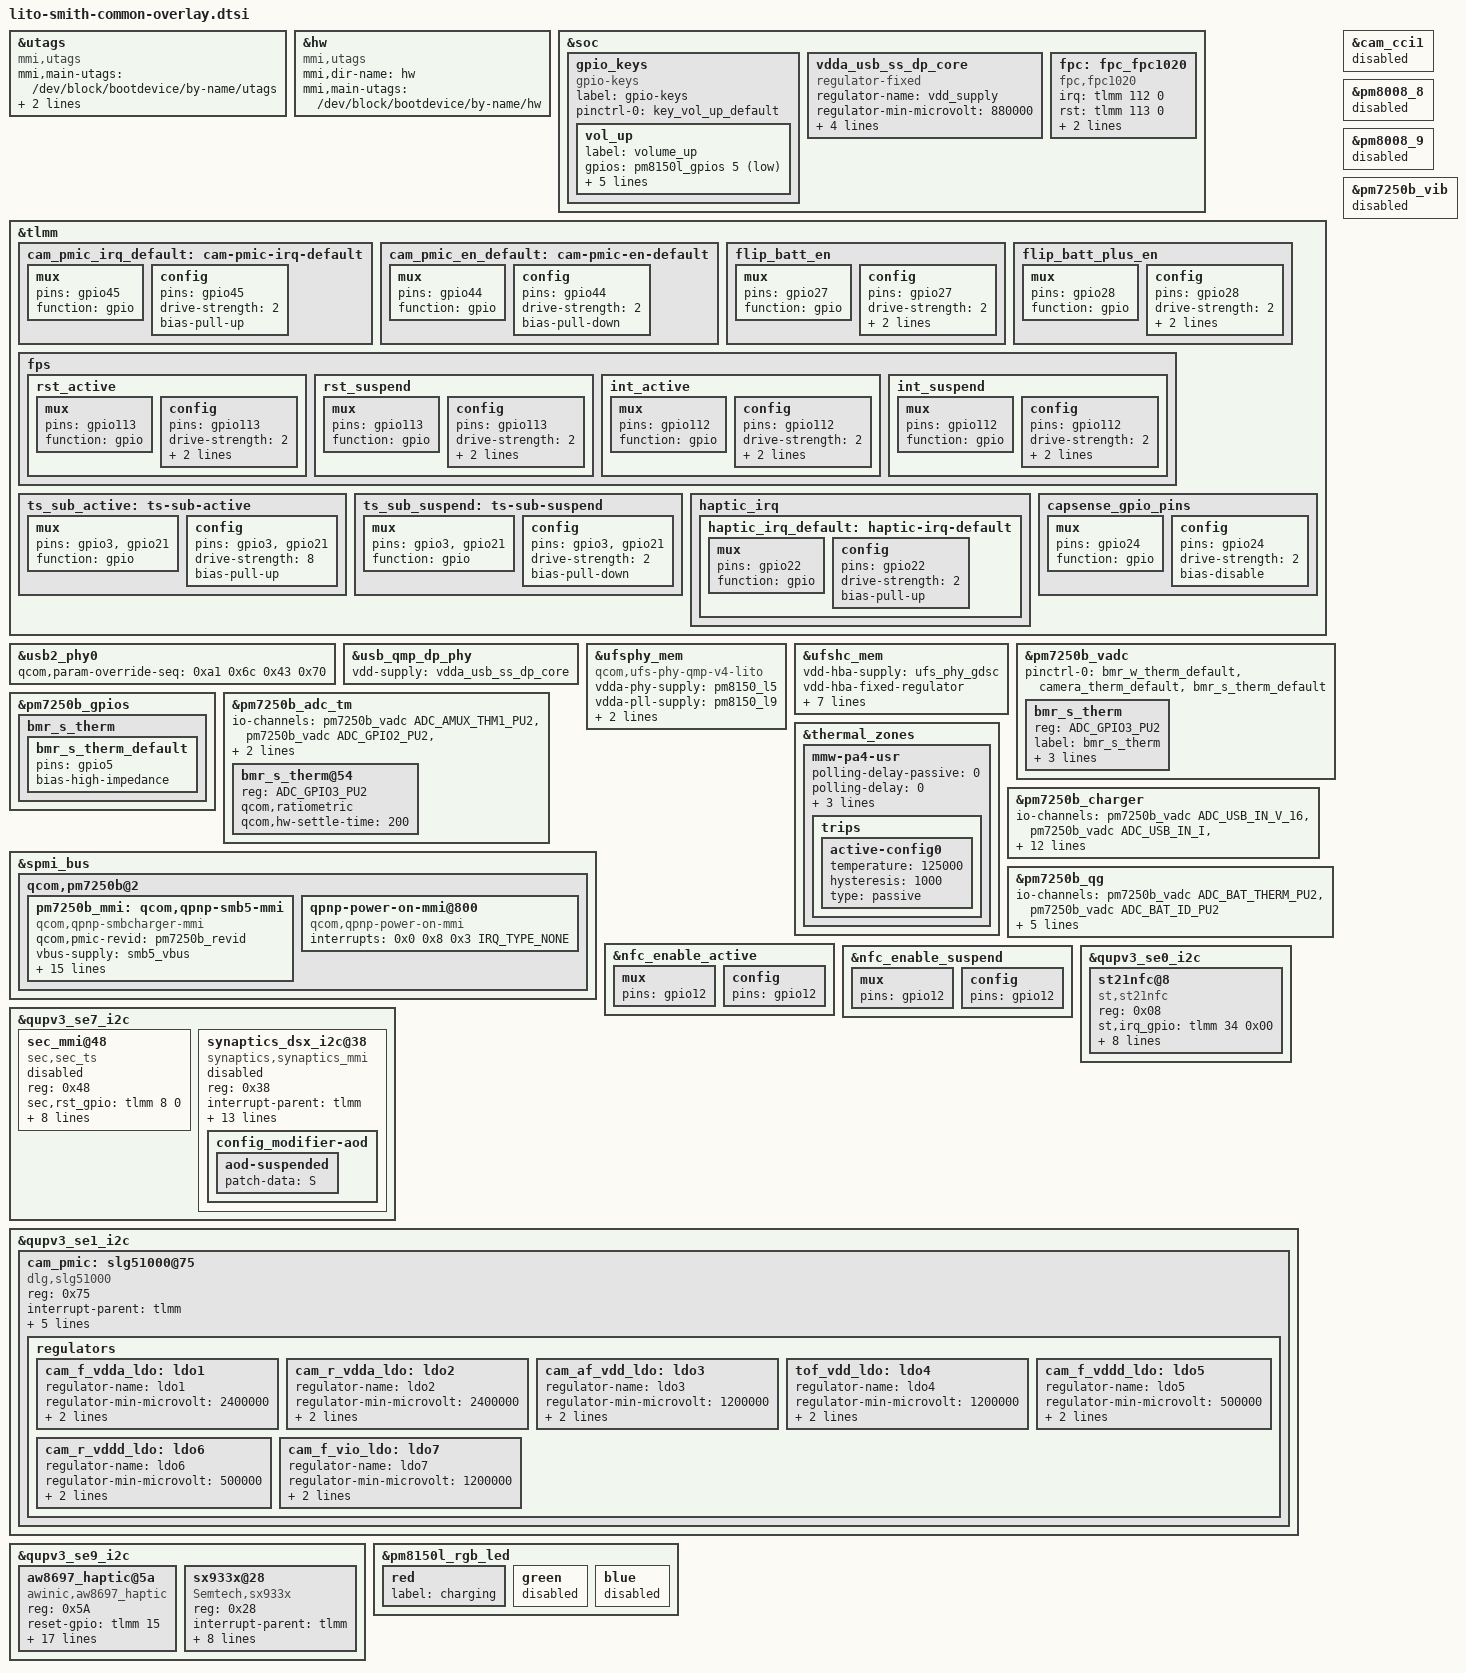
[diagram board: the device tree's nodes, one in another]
#include <dt-bindings/interrupt-controller/arm-gic.h>
#include <dt-bindings/gpio/gpio.h>
#include "carrier-channel-ids.dtsi"
#include "lito-pmic-overlay.dtsi"
#include "lito-thermal-overlay.dtsi"
#include "camera/lito-camera-sensor-mot-smith.dtsi"

&utags {
	compatible = "mmi,utags";
	mmi,main-utags = "/dev/block/bootdevice/by-name/utags";
	mmi,backup-utags = "/dev/block/bootdevice/by-name/utagsBackup";
};

&hw {
	compatible = "mmi,utags";
	mmi,dir-name = "hw";
	mmi,main-utags = "/dev/block/bootdevice/by-name/hw";
};

&soc {
	gpio_keys {
		compatible = "gpio-keys";
		label = "gpio-keys";

		pinctrl-names = "default";
		pinctrl-0 = <&key_vol_up_default>;

		vol_up {
			label = "volume_up";
			gpios = <&pm8150l_gpios 5 GPIO_ACTIVE_LOW>;
			linux,input-type = <1>;
			linux,code = <KEY_VOLUMEUP>;
			gpio-key,wakeup;
			debounce-interval = <15>;
			linux,can-disable;
		};
	};

	vdda_usb_ss_dp_core: vdda_usb_ss_dp_core {
		compatible = "regulator-fixed";
		regulator-name = "vdd_supply";
		regulator-min-microvolt = <880000>;
		regulator-max-microvolt = <880000>;
		enable-active-high;
		gpio = <&pm8150l_gpios 12 GPIO_ACTIVE_HIGH>;
		pinctrl-names = "default";
		pinctrl-0 = <&usb_eldo13>;
	};

	fpc: fpc_fpc1020 {
		compatible = "fpc,fpc1020";
		status = "ok";
		irq = <&tlmm 112 0>;
		rst = <&tlmm 113 0>;
		pinctrl-names = "default", "suspend";
		pinctrl-0 = <&int_active &rst_active>;
		pinctrl-1 = <&int_suspend &rst_suspend>;
	};
};

&tlmm{
	cam_pmic_irq_default: cam-pmic-irq-default {
		mux {
			pins = "gpio45";
			function = "gpio";
		};
		config {
		        pins = "gpio45";
			drive-strength = <2>; /* 2 mA */
			bias-pull-up;
		};
	};

	cam_pmic_en_default: cam-pmic-en-default {
		mux {
			pins = "gpio44";
			function = "gpio";
		};
		config {
			pins = "gpio44";
			drive-strength = <2>;
			bias-pull-down;
		};
	};

	flip_batt_en: flip_batt_en {
		mux {
			pins = "gpio27";
			function = "gpio";
		};
		config {
			pins = "gpio27";
			drive-strength = <2>;
			bias-pull-up;
			output-high;
		};
	};

	flip_batt_plus_en: flip_batt_plus_en {
		mux {
			pins = "gpio28";
			function = "gpio";
		};
		config {
			pins = "gpio28";
			drive-strength = <2>;
			bias-pull-up;
			output-high;
		};
	};

	fps {
		rst_active: rst_active {
			mux {
				pins = "gpio113";
				function = "gpio";
			};
			config {
				pins = "gpio113";
				drive-strength = <2>;
				bias-disable;
				output-low;
			};
		};

		rst_suspend: rst_suspend{
			mux {
				pins = "gpio113";
				function = "gpio";
			};

			config {
				pins = "gpio113";
				drive-strength = <2>;
				bias-pull-down;
				output-high;
			};
		};

		int_active: int_active {
			mux {
				pins = "gpio112";
				function = "gpio";
			};

			config {
				pins = "gpio112";
				drive-strength = <2>;
				bias-pull-down;
				input-enable;
			};
		};

		int_suspend: int_suspend{
			mux {
				pins = "gpio112";
				function = "gpio";
			};

			config {
				pins = "gpio112";
				drive-strength = <2>;
				bias-pull-down;
				input-enable;
			};
		};
	};

	ts_sub_active: ts-sub-active {
		mux {
			pins = "gpio3", "gpio21";
			function = "gpio";
		};
		config {
			pins = "gpio3", "gpio21";
			drive-strength = <8>;
			bias-pull-up;
		};
	};

	ts_sub_suspend: ts-sub-suspend {
		mux {
			pins = "gpio3", "gpio21";
			function = "gpio";
		};
		config {
			pins = "gpio3", "gpio21";
			drive-strength = <2>;
			bias-pull-down;
		};
	};
};

&usb2_phy0 {
	qcom,param-override-seq = <0xa1 0x6c
				0x43 0x70>;
};

&usb_qmp_dp_phy {
	vdd-supply = <&vdda_usb_ss_dp_core>;
};

&ufsphy_mem {
	compatible = "qcom,ufs-phy-qmp-v4-lito";

	vdda-phy-supply = <&pm8150_l5>;
	vdda-pll-supply = <&pm8150_l9>;
	vdda-phy-max-microamp = <90200>;
	vdda-pll-max-microamp = <19000>;

	status = "ok";
};

&ufshc_mem {
	vdd-hba-supply = <&ufs_phy_gdsc>;
	vdd-hba-fixed-regulator;
	vcc-supply = <&pm8150a_l7>;
	vcc-voltage-level = <2950000 2960000>;
	vccq2-supply = <&pm8150_s4>;
	vcc-max-microamp = <800000>;
	vccq2-max-microamp = <800000>;

	qcom,vddp-ref-clk-supply = <&pm8150_l9>;
	qcom,vddp-ref-clk-max-microamp = <100>;

	status = "ok";
};

&pm7250b_vadc {
	pinctrl-0 = <
		&bmr_w_therm_default
		&camera_therm_default
		&bmr_s_therm_default
	>;

	bmr_s_therm {
		reg = <ADC_GPIO3_PU2>;
		label = "bmr_s_therm";
		qcom,ratiometric;
		qcom,hw-settle-time = <200>;
		qcom,pre-scaling = <1 1>;
	};
};

&pm7250b_gpios {
	bmr_s_therm {
		bmr_s_therm_default: bmr_s_therm_default {
			pins = "gpio5";
			bias-high-impedance;
		};
	};
};

&pm7250b_adc_tm {
	io-channels = <&pm7250b_vadc ADC_AMUX_THM1_PU2>,
			<&pm7250b_vadc ADC_GPIO2_PU2>,
			<&pm7250b_vadc ADC_GPIO3_PU2>,
			<&pm7250b_vadc ADC_GPIO4_PU2>;

	bmr_s_therm@54 {
		reg = <ADC_GPIO3_PU2>;
		qcom,ratiometric;
		qcom,hw-settle-time = <200>;
	};
};

&thermal_zones {
	mmw-pa4-usr {
		polling-delay-passive = <0>;
		polling-delay = <0>;
		thermal-governor = "user_space";
		thermal-sensors = <&pm7250b_adc_tm ADC_GPIO3_PU2>;
		wake-capable-sensor;
		trips {
			active-config0 {
				temperature = <125000>;
				hysteresis = <1000>;
				type = "passive";
			};
		};
	};
};

&pm7250b_charger {
	status = "ok";
	io-channels = <&pm7250b_vadc ADC_USB_IN_V_16>,
		      <&pm7250b_vadc ADC_USB_IN_I>,
		      <&pm7250b_vadc ADC_CHG_TEMP>,
		      <&pm7250b_vadc ADC_DIE_TEMP>,
		      <&pm7250b_vadc ADC_AMUX_THM3_PU2>,
		      <&pm7250b_vadc ADC_SBUx>,
		      <&pm7250b_vadc ADC_VPH_PWR>;
	io-channel-names = "usb_in_voltage",
			   "usb_in_current",
			   "chg_temp",
			   "die_temp",
			   "conn_temp",
			   "sbux_res",
			   "vph_voltage";
	qcom,battery-data = <&mot_batterydata>;
	qcom,auto-recharge-soc = <98>;
	qcom,step-charging-enable;
	qcom,charger-temp-max = <800>;
	qcom,smb-temp-max = <800>;
	qcom,suspend-input-on-debug-batt;
	qcom,fcc-stepping-enable;
};

&spmi_bus {
	qcom,pm7250b@2 {
		pm7250b_mmi: qcom,qpnp-smb5-mmi {
			compatible = "qcom,qpnp-smbcharger-mmi";
			qcom,pmic-revid = <&pm7250b_revid>;
			vbus-supply = <&smb5_vbus>;
			mmi,fg-main-psy = "fg_main_battery";
			mmi,fg-flip-psy = "fg_flip_battery";
			status = "ok";
			qcom,enable-charging-limit;
			qcom,enable-factory-poweroff;
			qcom,upper-limit-capacity = <75>;
			qcom,lower-limit-capacity = <60>;
			qcom,mmi-temp-zones-main = <0 4200 240 0>,
					<10 4200 600 240>,
					<15 0 600 600>,
					<45 4200 1205 840>,
					<60 4200 600 0>;
			qcom,iterm-ma-main = <80>;
			qcom,mmi-temp-zones-flip = <0 4200 250 0>,
					<10 4200 610 250>,
					<15 0 610 610>,
					<45 4200 1225 860>,
					<60 4200 610 0>;
			qcom,iterm-ma-flip = <80>;
			qcom,vfloat-comp-uv = <20000>;
		};
	};
};

&pm7250b_qg {
	status = "ok";
	io-channels = <&pm7250b_vadc ADC_BAT_THERM_PU2>,
		      <&pm7250b_vadc ADC_BAT_ID_PU2>;
	io-channel-names = "batt-therm",
			   "batt-id";
	qcom,battery-data = <&mot_batterydata>;
	qcom,qg-iterm-ma = <100>;
	qcom,hold-soc-while-full;
	qcom,linearize-soc;
	qcom,cl-feedback-on;
};

&cam_cci1 {
	status = "disabled";
};

/* ST54JNFC */
&nfc_enable_active {
	mux {
		pins = "gpio12";
	};
	config {
		pins = "gpio12";
	};
};

&nfc_enable_suspend {
	mux {
		pins = "gpio12";
	};
	config {
		pins = "gpio12";
	};
};

&qupv3_se0_i2c {
	status = "ok";

	st21nfc@8 {
		compatible = "st,st21nfc";
		status = "ok";
		reg = <0x08>;
		st,irq_gpio = <&tlmm 34 0x00>;
		st,reset_gpio = <&tlmm 12 0x00>;
		st,clkreq_gpio = <&tlmm 31 0x00>;
		interrupt-parent = <&tlmm>;
		interrupts = <34 0>;
		interrupt-names = "nfc_irq";
		pinctrl-names = "nfc_active", "nfc_suspend";
		pinctrl-0 = <&nfc_int_active &nfc_enable_active &nfc_clk_req_active>;
		pinctrl-1 = <&nfc_int_suspend &nfc_enable_suspend &nfc_clk_req_suspend>;
	};
};

&qupv3_se7_i2c {
	status = "ok";
	sec_mmi@48 {
		status = "/chosen","mmi,panel_name","contains","boe","csot";
		compatible = "sec,sec_ts";
		reg = <0x48>;
		sec,rst_gpio = <&tlmm 8 0>;
		sec,irq_gpio = <&tlmm 9 0>;
		sec,irq_type = <0x2008>; /*IRQF_TRIGGER_LOW | IRQF_ONESHOT*/
		sec,max_coords = <876 2142>;
		sec,usb-charger-detection;
		sec,regulator_dvdd = "pm8150a_l1";
		sec,regulator_avdd = "pm8150_l16";
		pinctrl-names = "on_state", "off_state";
		pinctrl-0 = <&ts_active>;
		pinctrl-1 = <&ts_active>;
	};

	synaptics_dsx_i2c@38 {
		status = "/chosen","mmi,panel_name_s","contains","boe";
		compatible = "synaptics,synaptics_mmi";
		reg = <0x38>;
		interrupt-parent = <&tlmm>;
		interrupts = <3 0>;
		gpios = <&tlmm 3 0>, /* IRQ */
			<&tlmm 21 0>; /* RESET */
		touch_vdd-supply = <&pm8150a_l1>;
		vdd_quirk-supply = <&pm8150_l16>;
		synaptics,gpio-config;
		pinctrl-names = "default", "active";
		pinctrl-0 = <&ts_sub_active>;
		pinctrl-1 = <&ts_sub_active>;
		synaptics,splash-screen-mode;
		synaptics,control-dsi = <1>;
		synaptics,bound-display = "qcom,mdss_dsi_mot_boe_269_800x600_cmd_v2";
		synaptics,class-entry-name = "secondary";
		config_modifier-names = "aod";
			config_modifier-aod {
			aod-suspended {
				/* Power->sleep; */
				patch-data = "S";
			};
		};
	};
};

&qupv3_se1_i2c {
	status = "ok";

	cam_pmic: slg51000@75{
		compatible = "dlg,slg51000";
		reg = <0x75>;

		interrupt-parent = <&tlmm>;
		interrupts = <45 IRQ_TYPE_LEVEL_HIGH>;
		dlg,cs-gpios = <&tlmm 44 0>;

		pinctrl-names = "default";
		pinctrl-0 = <&cam_pmic_irq_default &cam_pmic_en_default &flip_batt_en &flip_batt_plus_en>;

		regulators {
			cam_f_vdda_ldo: ldo1 {
				regulator-name = "ldo1";
				regulator-min-microvolt = <2400000>;
				regulator-max-microvolt = <3300000>;
				regulator-boot-on;
			};

			cam_r_vdda_ldo: ldo2 {
				regulator-name = "ldo2";
				regulator-min-microvolt = <2400000>;
				regulator-max-microvolt = <3300000>;
				regulator-boot-on;
			};

			cam_af_vdd_ldo: ldo3 {
				regulator-name = "ldo3";
				regulator-min-microvolt = <1200000>;
				regulator-max-microvolt = <3750000>;
				regulator-boot-on;
			};

			tof_vdd_ldo: ldo4 {
				regulator-name = "ldo4";
				regulator-min-microvolt = <1200000>;
				regulator-max-microvolt = <3750000>;
				regulator-boot-on;
			};

			cam_f_vddd_ldo: ldo5 {
				regulator-name = "ldo5";
				regulator-min-microvolt = <500000>;
				regulator-max-microvolt = <1200000>;
				regulator-boot-on;
			};

			cam_r_vddd_ldo: ldo6 {
				regulator-name = "ldo6";
				regulator-min-microvolt = <500000>;
				regulator-max-microvolt = <1200000>;
				regulator-boot-on;
			};

			cam_f_vio_ldo: ldo7 {
				regulator-name = "ldo7";
				regulator-min-microvolt = <1200000>;
				regulator-max-microvolt = <3750000>;
				regulator-boot-on;
			};
		};
	};
};

&pm8008_8 {
	status = "disabled";
};

&pm8008_9 {
	status = "disabled";
};

&spmi_bus {
	qcom,pm7250b@2 {
		qpnp-power-on-mmi@800 {
			compatible = "qcom,qpnp-power-on-mmi";
			interrupts = <0x0 0x8 0x3 IRQ_TYPE_NONE>;
			interrupt-names = "kpdpwr-bark";
		};
	};
};

&tlmm {
	haptic_irq {
		haptic_irq_default: haptic-irq-default {
			mux {
				pins = "gpio22";
				function = "gpio";
			};
			config {
				pins = "gpio22";
				drive-strength = <2>;   /* 2 mA */
				bias-pull-up;
			};
		};
	};

	capsense_gpio_pins: capsense_gpio_pins {
		mux {
			pins = "gpio24";
			function = "gpio";
		};
		config {
			pins = "gpio24";
			drive-strength = <2>;
			bias-disable;
		};
	};
};

&qupv3_se9_i2c {
	status = "ok";
	aw8697_haptic@5a {
		status = "okay";
		compatible = "awinic,aw8697_haptic";
		reg = <0x5A>;
		reset-gpio = <&tlmm 15 0>;
		irq-gpio = <&tlmm 22 0>;
		vib_mode = <1>;   /*mode:   RAM mode->0; CONT mode -> 1*/
		vib_f0_pre = <1700>;
		vib_f0_cali_percen = <7>;
		vib_cont_drv_lev = <135>;
		vib_cont_drv_lvl_ov = <140>;
		vib_cont_td = <0x009a>;
		vib_cont_zc_thr = <0x0ff1>;
		vib_cont_num_brk = <3>;
		vib_f0_coeff = <260>; /*Don't modify it    2.604167*/
		vib_f0_trace_parameter = <0x05 0x03 0x02 0x0f>;
		vib_bemf_config = <0x10 0x08 0x03 0xf8>;
		vib_sw_brake = <0x2c>;
		vib_tset = <0x12>;
		vib_r_spare = <0x68>;
                vib_bstdbg = <0x30 0xeb 0xd4 0 0 0>;
		pinctrl-names = "default";
		pinctrl-0 = <&haptic_irq_default>;
	};

	sx933x@28 {
		compatible = "Semtech,sx933x";
		reg = <0x28>;
		interrupt-parent = <&tlmm>;
		interrupts = <24 0>;
		Semtech,nirq-gpio = <&tlmm 24 0x00>;
		pinctrl-names = "default";
		pinctrl-0 = <&capsense_gpio_pins>;
		cap_vdd-supply = <&pm8150_l13>;
		Semtech,reg-num = <40>;
		Semtech,button-flag = <0x1F>;
		Semtech,reg-init = <0x8020 0x1F0000
			0x8024 0x000008ae /*again 3.3pf*/
			0x8028 0x3ffa8000
			0x802C 0x300008d4
			0x8030 0x3ffb8000
			0x8034 0x00000876
			0x8038 0x3fbf8000
			0x803C 0x20000876
			0x8040 0x3dff8000
			0x8044 0x20000876
			0x8048 0x2fff8000
			0x8054 0x00302300 /*ph0*/
			0x8058 0x20600c00
			0x805c 0x00000000
			0x8064 0x00460000
			0x806C 0x30003000
			0x8074 0x083b4000 /*ph1*/
			0x8078 0x20600b00
			0x807c 0x00000000
			0x8094 0x09103700 /*ph2*/
			0x8098 0x20600c00
			0x809c 0x00000000
			0x80A4 0x00720000
			0x80B4 0x093b3200 /*ph3*/
			0x80b8 0x20600c00
			0x80bc 0x00000000
			0x80C4 0x00640000
			0x80D4 0x0a104000 /*ph4*/
			0x80d8 0x20600c00
			0x80dc 0x00000000
			0x80E4 0x00ff0000
			0x4054 0x00010400
			0x801c 0x00000033
			0x80ac 0x07000A00
			0x80b0 0x00150000
			0x80cc 0x19001e00
			0x80d0 0x00010000
			0x8124 0x0400000c
			0x8128 0x00000000
			0x4004 0x7F >;
	};
};

&pm7250b_vib {
	status = "disabled";
};

&pm8150l_rgb_led {
	red {
		label = "charging";
	};

	green {
		status = "disabled";
	};

	blue {
		status = "disabled";
	};
};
